# ESP32C6_RADIO register map
File version: 0.1.0
Registers are 32-bit, read-write, no defined reset value unless marked. A register's access mark holds for its fields unless they carry their own. Offsets are from the block's base; [hi:lo] are bit positions; {n}, {i} and the like mark numbered series.

## FE — Front end Unused by the library (it has no C6 transmit path). Evidence marked *decompile* in this section comes from C6 `libphy.a` `phy_reg.o`, `phy_pbus.o`, `phy_init.o` and `phy_tx_cal.o`, `librftest.a` `rf_test.o`, `esp_phy_api.o`, `phy_test.o` and `wifi.o`, and the C6 ROM. How the vendor functions drive the front end: - `esp_phy_wifi_tx_tone(start, chan, backoff)` (`wifiscwout()`) tunes with `chip_v7_set_chan(chan, 0)` (above 2000 the argument is MHz, truncated to a channel: 2437 to 2441 all give channel 6), forces the analog TX chain on through pbus debug mode (`ram_txcal_debuge_mode()`: `pbus_force_mode(1)`, `ram_pbus_xpd_tx_on()`, the calibrated DC offset, the TX clock), and starts tone 0 at frequency 0, attenuated by the calibrated value + backoff + 12 in quarter dB. It never calls `force_txon()`. Stopping runs ROM `txcal_work_mode()` (0x400047d6): tone off, TX clock off, pbus back to receive and to normal mode. On the bench the carrier arrives at the channel centre (*measured* bench 2026-10-11). - `ram_stop_tx_tone()` stops the tones and selects the data path, leaving the pbus forcing and the TX clock on: the C6 counterpart of the C5's `phy_stop_tx_tone(1)`. The DAC engine played with the source left at 0 (see "Dump and DAC engine"); with 3 it is untested. - `force_txon(on)` clears `0x600a70dc` bit 16 and sets FE_RX_FORCE to 2, then FE_TX_FORCE to 3; off goes in reverse. - In `force_txon_mode(on, bt, idx)` the second argument, which the ESP32-S3 page calls mode, acts as a BT flag: the function always writes the power index force (FE_PWR_INDEX_FORCE = `on`, index in FE_PWR_INDEX), then calls `force_txon(0)` and `force_txon(on)`; only with the flag it first adds 32 to the index, stops the hardware frequency engine (FE_HW_FREQ_STOP), writes `0x600af4b4` bit 0, FE_BT_FORCE and `0x600a28a0` bits 31:30 (all ones with `on`, 0 without), and restarts the engine if it ran before. - `set_dump_mode(x)` clears FE_R958_REG bits 1:0 and writes `0x600a70b8` bits 2:0 = 1 when x is 0, else 0 (C6 `librftest.a` `phy_test.o`).
Base 0x600A0000
0xC0 RC0 — Hardware frequency engine stop
  [26] HW_FREQ_STOP — The hardware frequency engine stop: the BT branch of `force_txon_mode()` stops the engine (this bit) and restarts it afterwards if it ran before.
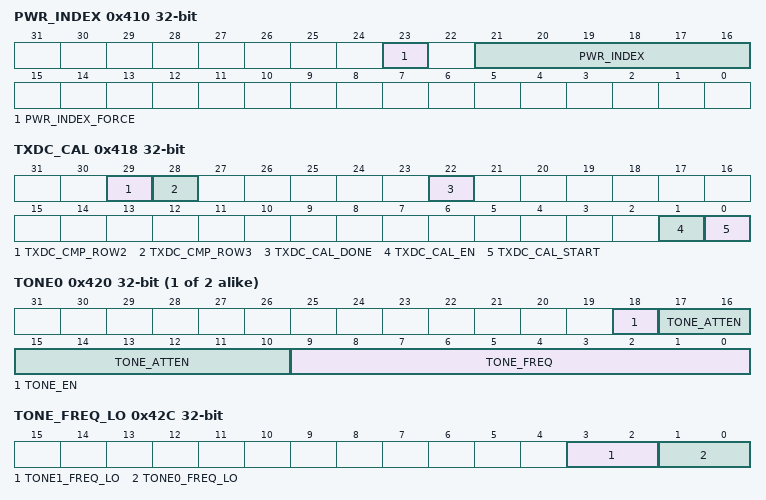
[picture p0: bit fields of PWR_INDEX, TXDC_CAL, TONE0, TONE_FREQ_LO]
0x410 PWR_INDEX — Power index force
  [23] PWR_INDEX_FORCE — Forces the power index FE_PWR_INDEX. `force_txon_mode()` sets it to its `on` argument, so `force_txon_mode(0, ...)` releases the force. Evidence: *decompile* C6 `libphy.a` `phy_reg.o` (`force_txon_mode()` passes `on != 0`), C6 ROM `phy_force_pwr_index` (0x400057e2, bit 23 = its first argument)
  [21:16] PWR_INDEX — The forced power index: `force_txon_mode(on, bt, idx)` writes idx here, plus 32 with the BT flag.
0x414 DAC_SRC — DAC source select
  [1:0] DAC_SRC — DAC source select as the vendor uses it: `ram_start_tx_tone_step()` writes 0 with a tone and 3 without, `ram_stop_tx_tone()` writes 3; the ROM tone functions leave it alone. The DAC engine plays with 0 (see "Dump and DAC engine"); with 3 it is untested. Evidence: *decompile*; *measured* bench 2026-10-11
0x418 TXDC_CAL — TX DC calibration comparator Layout as libphy `txdc_cal_new()` drives it. The result goes into pbus rows 2 and 3 through `rom_pbus_force_test()`. The ROM `txdc_cal()` (0x4000761e) uses another layout on the same register and no C6 library calls it. Shell writes sometimes made a carrier, not reproducibly. Evidence: *decompile* `libphy.a` `phy_tx_cal.o`, C6 ROM; *measured* bench 2026-10-11
  [29] TXDC_CMP_ROW2 ro — Comparator output for pbus row 2 (presumably I).
  [28] TXDC_CMP_ROW3 ro — Comparator output for pbus row 3 (presumably Q).
  [22] TXDC_CAL_DONE ro — Calibration done.
  [1] TXDC_CAL_EN — Calibration enable.
  [0] TXDC_CAL_START — Calibration start.
{0x420+4i} TONE{i} (i=0..1) — Tones 0 and 1: enable, attenuation, frequency The vendor keeps bits 31:28 and writes 0 to bits 27:19. The vendor CW leaves tone 0 at 0x00068400 or 0x00068c00: frequency 0, a carrier at the LO. Evidence: *decompile*; *measured* bench 2026-10-11
  [18] TONE_EN — Tone enable.
  [17:10] TONE_ATTEN — The attenuation, negated.
  [9:0] TONE_FREQ — The frequency >> 2. libphy `ram_start_tx_tone_step()` puts the frequency's low two bits in FE_TONE_FREQ_LO_REG; the ROM version splits the frequency so only while FE_TONE0_REG bit 29 is set, else it writes it unshifted and leaves FE_TONE_FREQ_LO_REG alone.
0x42C TONE_FREQ_LO — Fine tone frequency: the low two bits of each tone's frequency libphy `ram_start_tx_tone_step()` puts the frequency's low two bits here. The ROM version does so only while FE_TONE0_REG bit 29 is set, else it writes the frequency unshifted and leaves this register alone. Evidence: *decompile*
  [3:2] TONE1_FREQ_LO — Low two bits of tone 1's frequency.
  [1:0] TONE0_FREQ_LO — Low two bits of tone 0's frequency.
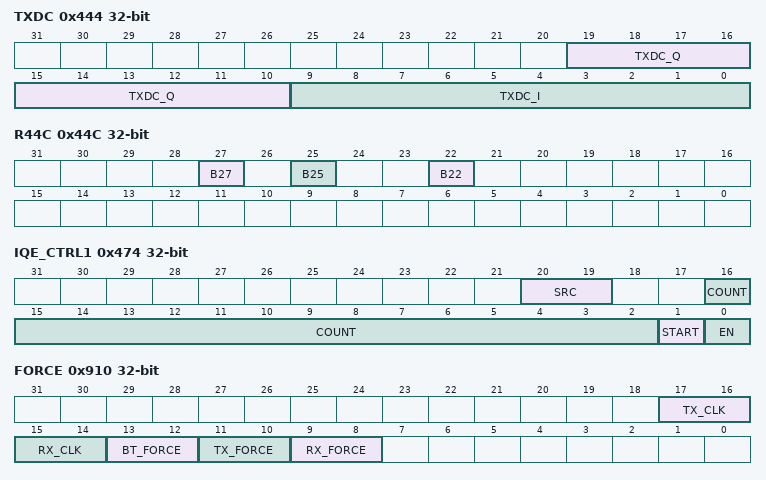
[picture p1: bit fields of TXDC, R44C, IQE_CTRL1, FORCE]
0x444 TXDC — TX DC value The C6 `set_txdc_dig(i, q)`, the only code that writes the register, writes only FE_TXDC_I and FE_TXDC_Q; the identical C61 function writes 0x600a0c08, the register upstream's first C5 code drove CPU-paced I/Q through (`TXDC_REG`, `emit_iq()`). Untested on the C6. Evidence: *decompile* C6 and C61 `librftest.a` `phy_test.o`; *upstream* `git show e605684:main/c5_main.c:32, 211-238`
  [19:10] TXDC_Q — TX DC value, Q.
  [9:0] TXDC_I — TX DC value, I.
0x44C R44C — Unknown; init sets bits 27 and 25 and clears bit 22 ROM `fe_reg_init()` and libphy `reg_set_new()` set bits 27 and 25 and clear bit 22 at init, at the step where the C61's `phy_fe_reg_init()` sets bits 25 (IQ swap) and 26 (inject) of its TX DC register 0x600a0c08. That 25 and 27 are the C6's IQ swap and inject bits is a guess. Evidence: *decompile* (the writes; C61 `libphy.a` `phy_reg.o`); *speculative* (the meaning)
  [27] B27 — Set at init.
  [25] B25 — Set at init.
  [22] B22 — Cleared at init.
0x470 IQE_CTRL0 — IQ estimator: mode The estimator sums the 80 MHz receive input in hardware (ROM `rom_iq_est_enable`, `dc_iq_est`); the library selects mode 1 for its paced receive and its trigger. Modes 0 to 3 gave the same sums in FE_IQE_POW_REG and FE_IQE_POW_I_REG. Evidence: *working* `lib/esp_sdr/src/esp_sdr_priv.h:119-121`, `lib/esp_sdr/src/esp_sdr_paced.c`; *measured* bench 2026-10-19 (modes)
  [27:26] MODE — Estimator mode; the library writes 1.
0x474 IQE_CTRL1 — IQ estimator: source, input count, start and enable A run sums IQE_COUNT + 1 inputs (at most 32768, 410 us), then stops; the sums can be read while it counts. Restarting is enable, then enable with start. Evidence: *working* `lib/esp_sdr/src/esp_sdr_priv.h:122-129`, `lib/esp_sdr/src/esp_sdr_paced.c`
  [20:19] SRC — Input select; the library writes 2 (the receive I/Q).
  [16:2] COUNT — Inputs to sum, minus one.
  [1] START — Set after IQE_EN to start a run.
  [0] EN — Enables the estimator.
0x488 IQE_SUM_I ro — IQ estimator: sum of I since the run started, times 64 (signed) Differencing two readings gives the sum over the inputs between them: the paced receive's boxcar decimator. Evidence: *working* `lib/esp_sdr/src/esp_sdr_paced.c`
0x48C IQE_SUM_Q ro — IQ estimator: sum of Q since the run started, times 64 (signed) Evidence: *working* `lib/esp_sdr/src/esp_sdr_paced.c`
0x490 IQE_POW ro — IQ estimator: sum of I squared plus Q squared since the run started, over 8 Over the full 80 MHz input, the 10-bit values (the dump's bits 19:10 and 9:0) squared: measured against the dump's own samples of the same inputs, 28 runs at three frequencies and four gains, DC from 1 to 19 and noise to strong Wi-Fi, all within 0.1 % once the count is matched by FE_IQE_SUM_I_REG. It keeps counting while the dump engine runs, so it is a wideband power detector next to a capture: the library's triggered snapshots difference it every 10 us and take the window's mean out with FE_IQE_SUM_I_REG and FE_IQE_SUM_Q_REG. Whether it saturates or wraps past 2^32 is not known: the library restarts the run every 8000 inputs. Evidence: *measured* bench 2026-10-20 (simultaneous dump and estimator); *working* `lib/esp_sdr/src/esp_sdr_trig.c`
0x494 IQE_POW_I ro — IQ estimator: sum of I squared since the run started, over 4 Measured as FE_IQE_POW_REG. Evidence: *measured* bench 2026-10-20
0x498 IQE_POW_Q ro — IQ estimator: sum of Q squared since the run started, over 4 Measured as FE_IQE_POW_REG. Evidence: *measured* bench 2026-10-20
0x49C IQE_CORR ro — IQ estimator: sum of I times Q since the run started, over 4 (signed) Measured as FE_IQE_POW_REG, with DCs and cross products of both signs. Evidence: *measured* bench 2026-10-20
0x910 FORCE — Receive, transmit and BT mode force pairs; receive and transmit clocks FE_RX_FORCE, FE_TX_FORCE and FE_BT_FORCE are force pairs, high bit force, low bit value: 0 released, 2 forced off, 3 forced on (inferred from all writers). Evidence: *decompile*
  [17:16] TX_CLK — Transmit clock, 3 on, 0 off, as ROM `set_txclk_en()` (0x40005268) writes it.
  [15:14] RX_CLK — Receive clock, 3 on, 0 off, as ROM `set_rxclk_en()` (0x4000528c) writes it.
  [13:12] BT_FORCE — BT mode force pair: 3 from the BT branch of `force_txon_mode()`, `txon_set(1)` and `bt_rx_force()`.
  [11:10] TX_FORCE — Transmit force pair: 3 from `force_txon(1)` and `txon_set(1)`; 2 from `force_txrx_off(1)` and ROM `phy_close_pa(1)`.
  [9:8] RX_FORCE — Receive force pair: 2 from `force_txon(1)`, `txon_set(1)` and `force_txrx_off(1)`; 3 from `bt_rx_force()` and ROM `fe_adc_on()`.
0x958 R958 — Unknown; `set_dump_mode()` clears bits 1:0
  [1:0] B1_0 — Cleared by `set_dump_mode(x)`. Evidence: C6 `librftest.a` `phy_test.o`
